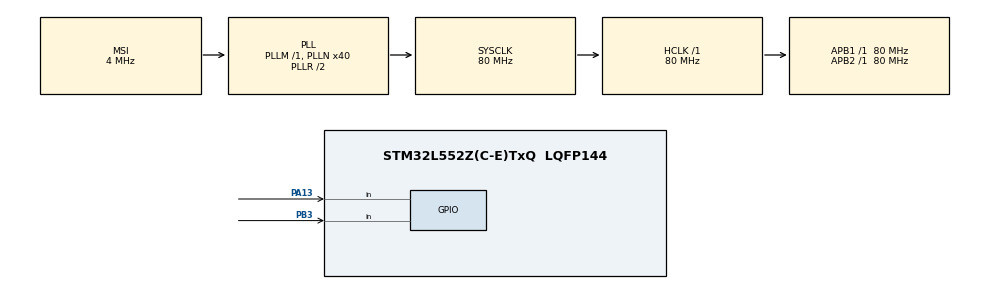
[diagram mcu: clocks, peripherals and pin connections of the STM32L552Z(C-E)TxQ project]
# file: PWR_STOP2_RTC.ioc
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Mcu.Family=STM32L5
Mcu.Name=STM32L552Z(C-E)TxQ
Mcu.Package=LQFP144
Mcu.TrustZone=disable
NVIC.PriorityGroup=NVIC_PRIORITYGROUP_3
PA13\ (JTMS/SWDIO).GPIO_PuPd=GPIO_PULLUP
PA13\ (JTMS/SWDIO).Signal=GPIO_Input
PB3\ (JTDO/TRACESWO).GPIO_PuPd=GPIO_PULLUP
PB3\ (JTDO/TRACESWO).Signal=GPIO_Input
ProjectManager.HeapSize=0x200
ProjectManager.StackSize=0x400
ProjectManager.TargetToolchain=EWARM V8.32
RCC.AHBFreq_Value=80000000
RCC.APB1Freq_Value=80000000
RCC.APB1TimFreq_Value=80000000
RCC.APB2Freq_Value=80000000
RCC.APB2TimFreq_Value=80000000
RCC.CortexFreq_Value=80000000
RCC.HCLKFreq_Value=80000000
RCC.HSE_VALUE=16000000
RCC.HSI48_VALUE=48000000
RCC.HSI_VALUE=16000000
RCC.LSE_VALUE=32768
RCC.MSI_VALUE=4000000
RCC.PLLN=40
RCC.SYSCLKFreq_VALUE=80000000
RCC.SYSCLKSource=RCC_SYSCLKSOURCE_PLLCLK
RCC.VCOOutputFreq_Value=160000000
VP_ICACHE_VS_ICACHE.Mode=DirectMappedCache
VP_PWR_VS_DBSignals.Mode=DisableDeadBatterySignals
board=custom

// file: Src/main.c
/* USER CODE BEGIN Header */
/**
  ******************************************************************************
  * @file    PWR/PWR_STOP2_RTC/Src/main.c
  * @author  MCD Application Team
  * @brief   This sample code shows how to use PWR HAL API to enter
  *          and exit the STOP 2 mode using RTC.
  ******************************************************************************
  * @attention
  *
  * Copyright (c) 2019 STMicroelectronics.
  * All rights reserved.
  *
  * This software is licensed under terms that can be found in the LICENSE file
  * in the root directory of this software component.
  * If no LICENSE file comes with this software, it is provided AS-IS.
  *
  ******************************************************************************
  */
/* USER CODE END Header */
#include "main.h"

/* USER CODE BEGIN PD */
#define LED_TOGGLE_DELAY         100UL
/* USER CODE END PD */

/* USER CODE BEGIN PV */
RTC_HandleTypeDef RTCHandle;
static uint32_t TimingDelay = LED_TOGGLE_DELAY;
/* USER CODE END PV */

void SystemClock_Config(void);
static void MX_GPIO_Init(void);
static void MX_ICACHE_Init(void);
/* USER CODE BEGIN PFP */
static void SystemPower_Config(void);
/* USER CODE END PFP */

int main(void)
{
  /* USER CODE BEGIN 1 */
  /* STM32L5xx HAL library initialization:
       - Systick timer is configured by default as source of time base, but user
         can eventually implement his proper time base source (a general purpose
         timer for example or other time source), keeping in mind that Time base
         duration should be kept 1ms since PPP_TIMEOUT_VALUEs are defined and
         handled in milliseconds basis.
       - Set NVIC Group Priority to 3
       - Low Level Initialization
     */
  /* USER CODE END 1 */

  /* MCU Configuration--------------------------------------------------------*/

  /* Reset of all peripherals, Initializes the Flash interface and the Systick. */
  HAL_Init();

  /* Configure the system clock */
  SystemClock_Config();

  /* USER CODE BEGIN SysInit */
  HAL_PWREx_EnableVddIO2();
  /* USER CODE END SysInit */

  /* Initialize all configured peripherals */
  MX_GPIO_Init();
  MX_ICACHE_Init();
  /* USER CODE BEGIN 2 */
  /* Configure the system Power */
  SystemPower_Config();
  /* USER CODE END 2 */

  /* Infinite loop */
  /* USER CODE BEGIN WHILE */
  while (1)
  {

    /* Configure LED1 */
    BSP_LED_Init(LED1);

    /* Insert 5 second delay */
    HAL_Delay(5000);

    /* De-Configure LED1 */
    BSP_LED_DeInit(LED1);

    /* Disable all used wakeup source */
    HAL_RTCEx_DeactivateWakeUpTimer(&RTCHandle);

      /* Re-enable wakeup source */
    /* ## Setting the Wake up time ############################################*/
    /* RTC Wakeup Interrupt Generation:
      the wake-up counter is set to its maximum value to yield the longest
      stop time to let the current reach its lowest operating point.
      The maximum value is 0xFFFF, corresponding to about 33 sec. when
      RTC_WAKEUPCLOCK_RTCCLK_DIV = RTCCLK_Div16 = 16

      Wakeup Time Base = (RTC_WAKEUPCLOCK_RTCCLK_DIV /(LSI))
      Wakeup Time = Wakeup Time Base * WakeUpCounter
        = (RTC_WAKEUPCLOCK_RTCCLK_DIV /(LSI)) * WakeUpCounter
        ==> WakeUpCounter = Wakeup Time / Wakeup Time Base

      To configure the wake up timer to 60s the WakeUpCounter is set to 0xFFFF:
      Wakeup Time Base = 16 /(~32.000KHz) = ~0.5 ms
      Wakeup Time = 0.5 ms  * WakeUpCounter
      Therefore, with wake-up counter =  0xFFFF  = 65,535
         Wakeup Time =  0,5 ms *  65,535 = 32,7675 s ~ 33 sec. */
    HAL_RTCEx_SetWakeUpTimer_IT(&RTCHandle, 0x0FFFF, RTC_WAKEUPCLOCK_RTCCLK_DIV16, 0U);

    /* Enter STOP 2 mode */
    HAL_PWREx_EnterSTOP2Mode(PWR_STOPENTRY_WFI);

    /* ... STOP 2 mode ... */

    /* Re-configure the system clock to 110 MHz based on MSI, enable and
       select PLL as system clock source (PLL is disabled in STOP mode) */
    SystemClock_Config();
    /* USER CODE END WHILE */

  }
}

void SystemClock_Config(void)
{
  RCC_OscInitTypeDef RCC_OscInitStruct = {0};
  RCC_ClkInitTypeDef RCC_ClkInitStruct = {0};

  /** Configure the main internal regulator output voltage
  */
  if (HAL_PWREx_ControlVoltageScaling(PWR_REGULATOR_VOLTAGE_SCALE1) != HAL_OK)
  {
    Error_Handler();
  }

  /** Initializes the RCC Oscillators according to the specified parameters
  * in the RCC_OscInitTypeDef structure.
  */
  RCC_OscInitStruct.OscillatorType = RCC_OSCILLATORTYPE_MSI;
  RCC_OscInitStruct.MSIState = RCC_MSI_ON;
  RCC_OscInitStruct.MSICalibrationValue = RCC_MSICALIBRATION_DEFAULT;
  RCC_OscInitStruct.MSIClockRange = RCC_MSIRANGE_6;
  RCC_OscInitStruct.PLL.PLLState = RCC_PLL_ON;
  RCC_OscInitStruct.PLL.PLLSource = RCC_PLLSOURCE_MSI;
  RCC_OscInitStruct.PLL.PLLM = 1;
  RCC_OscInitStruct.PLL.PLLN = 40;
  RCC_OscInitStruct.PLL.PLLP = RCC_PLLP_DIV7;
  RCC_OscInitStruct.PLL.PLLQ = RCC_PLLQ_DIV2;
  RCC_OscInitStruct.PLL.PLLR = RCC_PLLR_DIV2;
  if (HAL_RCC_OscConfig(&RCC_OscInitStruct) != HAL_OK)
  {
    Error_Handler();
  }

  /** Initializes the CPU, AHB and APB buses clocks
  */
  RCC_ClkInitStruct.ClockType = RCC_CLOCKTYPE_HCLK|RCC_CLOCKTYPE_SYSCLK
                              |RCC_CLOCKTYPE_PCLK1|RCC_CLOCKTYPE_PCLK2;
  RCC_ClkInitStruct.SYSCLKSource = RCC_SYSCLKSOURCE_PLLCLK;
  RCC_ClkInitStruct.AHBCLKDivider = RCC_SYSCLK_DIV1;
  RCC_ClkInitStruct.APB1CLKDivider = RCC_HCLK_DIV1;
  RCC_ClkInitStruct.APB2CLKDivider = RCC_HCLK_DIV1;

  if (HAL_RCC_ClockConfig(&RCC_ClkInitStruct, FLASH_LATENCY_3) != HAL_OK)
  {
    Error_Handler();
  }
}

static void MX_ICACHE_Init(void)
{

  /** Enable instruction cache in 1-way (direct mapped cache)
  */
  if (HAL_ICACHE_ConfigAssociativityMode(ICACHE_1WAY) != HAL_OK)
  {
    Error_Handler();
  }
  if (HAL_ICACHE_Enable() != HAL_OK)
  {
    Error_Handler();
  }

}

static void MX_GPIO_Init(void)
{
  GPIO_InitTypeDef GPIO_InitStruct = {0};

  /* GPIO Ports Clock Enable */
  __HAL_RCC_GPIOE_CLK_ENABLE();
  __HAL_RCC_GPIOC_CLK_ENABLE();
  __HAL_RCC_GPIOF_CLK_ENABLE();
  __HAL_RCC_GPIOH_CLK_ENABLE();
  __HAL_RCC_GPIOA_CLK_ENABLE();
  __HAL_RCC_GPIOB_CLK_ENABLE();
  __HAL_RCC_GPIOG_CLK_ENABLE();
  __HAL_RCC_GPIOD_CLK_ENABLE();
  HAL_PWREx_EnableVddIO2();

  /*Configure GPIO pins : PE2 PE3 PE4 PE5
                           PE6 PE7 PE8 PE9
                           PE10 PE11 PE12 PE13
                           PE14 PE15 PE0 PE1 */
  GPIO_InitStruct.Pin = GPIO_PIN_2|GPIO_PIN_3|GPIO_PIN_4|GPIO_PIN_5
                          |GPIO_PIN_6|GPIO_PIN_7|GPIO_PIN_8|GPIO_PIN_9
                          |GPIO_PIN_10|GPIO_PIN_11|GPIO_PIN_12|GPIO_PIN_13
                          |GPIO_PIN_14|GPIO_PIN_15|GPIO_PIN_0|GPIO_PIN_1;
  GPIO_InitStruct.Mode = GPIO_MODE_ANALOG;
  GPIO_InitStruct.Pull = GPIO_NOPULL;
  HAL_GPIO_Init(GPIOE, &GPIO_InitStruct);

  /*Configure GPIO pins : PC13 PC14 PC15 PC0
                           PC1 PC2 PC3 PC6
                           PC7 PC8 PC9 PC10
                           PC11 PC12 */
  GPIO_InitStruct.Pin = GPIO_PIN_13|GPIO_PIN_14|GPIO_PIN_15|GPIO_PIN_0
                          |GPIO_PIN_1|GPIO_PIN_2|GPIO_PIN_3|GPIO_PIN_6
                          |GPIO_PIN_7|GPIO_PIN_8|GPIO_PIN_9|GPIO_PIN_10
                          |GPIO_PIN_11|GPIO_PIN_12;
  GPIO_InitStruct.Mode = GPIO_MODE_ANALOG;
  GPIO_InitStruct.Pull = GPIO_NOPULL;
  HAL_GPIO_Init(GPIOC, &GPIO_InitStruct);

  /*Configure GPIO pins : PF0 PF1 PF2 PF3
                           PF4 PF5 PF6 PF7
                           PF8 PF9 PF10 PF11
                           PF12 PF13 PF14 PF15 */
  GPIO_InitStruct.Pin = GPIO_PIN_0|GPIO_PIN_1|GPIO_PIN_2|GPIO_PIN_3
                          |GPIO_PIN_4|GPIO_PIN_5|GPIO_PIN_6|GPIO_PIN_7
                          |GPIO_PIN_8|GPIO_PIN_9|GPIO_PIN_10|GPIO_PIN_11
                          |GPIO_PIN_12|GPIO_PIN_13|GPIO_PIN_14|GPIO_PIN_15;
  GPIO_InitStruct.Mode = GPIO_MODE_ANALOG;
  GPIO_InitStruct.Pull = GPIO_NOPULL;
  HAL_GPIO_Init(GPIOF, &GPIO_InitStruct);

  /*Configure GPIO pins : PH0 PH1 PH3 */
  GPIO_InitStruct.Pin = GPIO_PIN_0|GPIO_PIN_1|GPIO_PIN_3;
  GPIO_InitStruct.Mode = GPIO_MODE_ANALOG;
  GPIO_InitStruct.Pull = GPIO_NOPULL;
  HAL_GPIO_Init(GPIOH, &GPIO_InitStruct);

  /*Configure GPIO pins : PA0 PA1 PA2 PA3
                           PA4 PA5 PA6 PA7
                           PA8 PA9 PA10 PA11
                           PA12 PA14 PA15 */
  GPIO_InitStruct.Pin = GPIO_PIN_0|GPIO_PIN_1|GPIO_PIN_2|GPIO_PIN_3
                          |GPIO_PIN_4|GPIO_PIN_5|GPIO_PIN_6|GPIO_PIN_7
                          |GPIO_PIN_8|GPIO_PIN_9|GPIO_PIN_10|GPIO_PIN_11
                          |GPIO_PIN_12|GPIO_PIN_14|GPIO_PIN_15;
  GPIO_InitStruct.Mode = GPIO_MODE_ANALOG;
  GPIO_InitStruct.Pull = GPIO_NOPULL;
  HAL_GPIO_Init(GPIOA, &GPIO_InitStruct);

  /*Configure GPIO pins : PB0 PB1 PB2 PB10
                           PB11 PB13 PB14 PB15
                           PB4 PB5 PB6 PB7
                           PB8 PB9 */
  GPIO_InitStruct.Pin = GPIO_PIN_0|GPIO_PIN_1|GPIO_PIN_2|GPIO_PIN_10
                          |GPIO_PIN_11|GPIO_PIN_13|GPIO_PIN_14|GPIO_PIN_15
                          |GPIO_PIN_4|GPIO_PIN_5|GPIO_PIN_6|GPIO_PIN_7
                          |GPIO_PIN_8|GPIO_PIN_9;
  GPIO_InitStruct.Mode = GPIO_MODE_ANALOG;
  GPIO_InitStruct.Pull = GPIO_NOPULL;
  HAL_GPIO_Init(GPIOB, &GPIO_InitStruct);

  /*Configure GPIO pins : PG0 PG1 PG2 PG3
                           PG4 PG5 PG6 PG7
                           PG8 PG9 PG10 PG12
                           PG13 PG14 PG15 */
  GPIO_InitStruct.Pin = GPIO_PIN_0|GPIO_PIN_1|GPIO_PIN_2|GPIO_PIN_3
                          |GPIO_PIN_4|GPIO_PIN_5|GPIO_PIN_6|GPIO_PIN_7
                          |GPIO_PIN_8|GPIO_PIN_9|GPIO_PIN_10|GPIO_PIN_12
                          |GPIO_PIN_13|GPIO_PIN_14|GPIO_PIN_15;
  GPIO_InitStruct.Mode = GPIO_MODE_ANALOG;
  GPIO_InitStruct.Pull = GPIO_NOPULL;
  HAL_GPIO_Init(GPIOG, &GPIO_InitStruct);

  /*Configure GPIO pins : PD8 PD9 PD10 PD11
                           PD12 PD13 PD14 PD15
                           PD0 PD1 PD2 PD3
                           PD4 PD5 PD6 PD7 */
  GPIO_InitStruct.Pin = GPIO_PIN_8|GPIO_PIN_9|GPIO_PIN_10|GPIO_PIN_11
                          |GPIO_PIN_12|GPIO_PIN_13|GPIO_PIN_14|GPIO_PIN_15
                          |GPIO_PIN_0|GPIO_PIN_1|GPIO_PIN_2|GPIO_PIN_3
                          |GPIO_PIN_4|GPIO_PIN_5|GPIO_PIN_6|GPIO_PIN_7;
  GPIO_InitStruct.Mode = GPIO_MODE_ANALOG;
  GPIO_InitStruct.Pull = GPIO_NOPULL;
  HAL_GPIO_Init(GPIOD, &GPIO_InitStruct);

  /*Configure GPIO pin : PA13 */
  GPIO_InitStruct.Pin = GPIO_PIN_13;
  GPIO_InitStruct.Mode = GPIO_MODE_INPUT;
  GPIO_InitStruct.Pull = GPIO_PULLUP;
  HAL_GPIO_Init(GPIOA, &GPIO_InitStruct);

  /*Configure GPIO pin : PB3 */
  GPIO_InitStruct.Pin = GPIO_PIN_3;
  GPIO_InitStruct.Mode = GPIO_MODE_INPUT;
  GPIO_InitStruct.Pull = GPIO_PULLUP;
  HAL_GPIO_Init(GPIOB, &GPIO_InitStruct);

}

/* USER CODE BEGIN 4 */

/**
  * @brief  System Power Configuration
  *         The system Power is configured as follow :
  *            + RTC Clocked by LSI
  *            + VREFINT OFF, with fast wakeup enabled
  *            + No IWDG
  *            + Automatic Wakeup using RTC clocked by LSI (after ~4s)
  * @param  None
  * @retval None
  */
static void SystemPower_Config(void)
{

  /* Configure RTC */
  RTCHandle.Instance = RTC;
  /* Set the RTC time base to 1s */
  /* Configure RTC prescaler and RTC data registers as follow:
    - Hour Format = Format 24
    - Asynch Prediv = Value according to source clock
    - Synch Prediv = Value according to source clock
    - OutPut = Output Disable
    - OutPutPolarity = High Polarity
    - OutPutType = Open Drain */
  RTCHandle.Init.HourFormat = RTC_HOURFORMAT_24;
  RTCHandle.Init.AsynchPrediv = RTC_ASYNCH_PREDIV;
  RTCHandle.Init.SynchPrediv = RTC_SYNCH_PREDIV;
  RTCHandle.Init.OutPut = RTC_OUTPUT_DISABLE;
  RTCHandle.Init.OutPutPolarity = RTC_OUTPUT_POLARITY_HIGH;
  RTCHandle.Init.OutPutType = RTC_OUTPUT_TYPE_OPENDRAIN;
  if(HAL_RTC_Init(&RTCHandle) != HAL_OK)
  {
    /* Initialization Error */
    Error_Handler();
  }
}

/**
  * @brief SYSTICK callback
  * @param None
  * @retval None
  */
void HAL_SYSTICK_Callback(void)
{
  if (TimingDelay != 0)
  {
    TimingDelay--;
  }
  else
  {
    /* Toggle LED1 */
    BSP_LED_Toggle(LED1);
    TimingDelay = LED_TOGGLE_DELAY;
  }
}
/* USER CODE END 4 */

void Error_Handler(void)
{
  /* USER CODE BEGIN Error_Handler_Debug */
  /* User can add his own implementation to report the HAL error return state */

  /* Configure LED3 for error handler */
  BSP_LED_Init(LED3);

  while (1)
  {
    BSP_LED_Toggle(LED3);
    HAL_Delay(200);
  }

  /* USER CODE END Error_Handler_Debug */
}
